# M3351 register map
File version: 1.0
Registers are 32-bit, read-write, reset 0x0 unless marked. A register's access mark holds for its fields unless they carry their own. Offsets are from the block's base; [hi:lo] are bit positions; 'fields as' and 'values as' point back to an identical list.

## TMR01 — TIMER Register Map
Base 0x40050000
Same registers: TMR01_NS 0x50050000
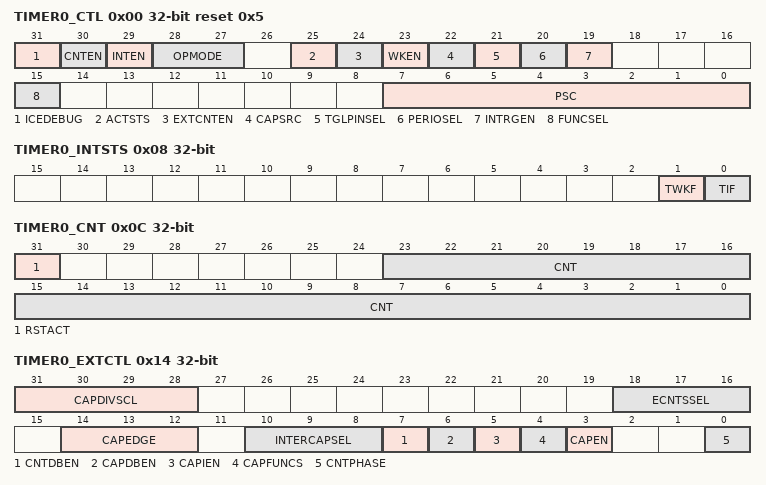
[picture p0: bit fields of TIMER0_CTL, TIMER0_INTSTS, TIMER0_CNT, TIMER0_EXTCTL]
0x00 TIMER0_CTL reset 0x5 — Timer0 Control Register
  [31] ICEDEBUG — ICE Debug Mode Acknowledge Disable Bit (Write Protect). TIMER counter will keep going no matter CPU is held by ICE or not. Note: This bit is write protected. Refer to the SYS_REGLCTL register.
    0=ICE debug mode acknowledgement effects TIMER counting; 1=ICE debug mode acknowledgement Disabled
  [30] CNTEN — Timer Counting Enable Bit. Note 3: Set enable/disable this bit needs 2 * TMR_CLK period to become active, user can read ACTSTS (TIMERx_CTL[25]) to check enable/disable command is completed or not.
    0=Stops/Suspends counting; 1=Starts counting
  [29] INTEN — Timer Interrupt Enable Bit. Note: If this bit is enabled, when the timer time-out interrupt flag TIF is set to 1, the timer interrupt signal is generated and inform to CPU.
    0=Timer time-out interrupt Disabled; 1=Timer time-out interrupt Enabled
  [28:27] OPMODE — Timer Counting Mode Select
    0=The timer controller is operated in One-shot mode; 1=The timer controller is operated in Periodic mode; 2=The timer controller is operated in Toggle-output mode; 3=The timer controller is operated in Continuous Counting mode
  [25] ACTSTS — Timer Active Status Bit (Read Only). This bit indicates the 24-bit up counter status. Note: This bit may active when CNT 0 transition to CNT 1.
    0=24-bit up counter is not active; 1=24-bit up counter is active
  [24] EXTCNTEN — Event Counter Mode Enable Bit. This bit is for external counting pin function enabled. Note: When timer is used as an event counter, this bit should be set to 1.
    0=Event counter mode Disabled; 1=Event counter mode Enabled
  [23] WKEN — Wake-up Function Enable Bit. If this bit is set to 1, while timer interrupt flag TIF (TIMERx_INTSTS[0]) is 1 and INTEN (TIMERx_CTL[29]) is enabled, the timer interrupt signal will generate a wake-up trigger event to CPU.
    0=Wake-up function Disabled if timer interrupt signal generated; 1=Wake-up function Enabled if timer interrupt signal generated
  [22] CAPSRC — Capture Pin Source Selection
    0=Capture Function source is from TMx_EXT (x= 0~3) pin; 1=Capture Function source is from internal ACMP output signal, internal clock (LIRC, HIRC), or external clock (HXT, LXT)
  [21] TGLPINSEL — Toggle-output Pin Select
    0=Toggle mode output to TMx (Timer Event Counter Pin); 1=Toggle mode output to TMx_EXT (Timer External Capture Pin)
  [20] PERIOSEL — Periodic Mode Behavior Selection Enable Bit. If updated CMPDAT value CNT, CNT will be reset to default value.
    0=The behavior selection in periodic mode is Disabled; 1=The behavior selection in periodic mode is Enabled
  [19] INTRGEN — Inter-timer Trigger Mode Enable Bit. Setting this bit will enable the inter-timer trigger capture function. The Timer0/2 will be in event counter mode and counting with external clock source or event.Also, Timer1/3 will be in trigger-counting mode of capture function. Note: For Timer1/3, this bit is ineffective and the read back value is always 0.
    0=Inter-Timer Trigger Capture mode Disabled; 1=Inter-Timer Trigger Capture mode Enabled
  [15] FUNCSEL — Function Selection
    0=Timer controller is used as timer function; 1=Timer controller is used as PWM function
  [7:0] PSC — Prescale Counter. Note: Updating the prescale counter value will reset internal 8-bit prescale counter and 24-bit up counter value.
0x04 TIMER0_CMP — Timer0 Comparator Register
  [23:0] CMPDAT — Timer Comparator Value. CMPDAT is a 24-bit compared value register. When the internal 24-bit up counter value is equal to CMPDAT value, the TIF (TIMERx_INTSTS[0] Timer Interrupt Flag) will be set to 1. Note 1: Never write 0x0 or 0x1 in CMPDAT field, or the core will run into unknown state. Note 2: When timer is operating at continuous counting mode, the 24-bit up counter will keep counting continuously even if user writes a new value into CMPDAT field. But if timer is operating at other modes, the 24-bit up counter will restart counting from 0 and using newest CMPDAT value to be the timer compared value while user writes a new value into CMPDAT field.
0x08 TIMER0_INTSTS — Timer0 Interrupt Status Register
  [1] TWKF — Timer Wake-up Flag. This bit indicates the interrupt wake-up flag status of timer. Note: This bit is cleared by writing 1 to it.
    0=Timer does not cause CPU wake-up; 1=CPU wake-up from Idle or Power-down mode if timer time-out interrupt signal generated
  [0] TIF — Timer Interrupt Flag. This bit indicates the interrupt flag status of Timer while 24-bit timer up counter CNT (TIMERx_CNT[23:0]) value reaches CMPDAT (TIMERx_CMP[23:0]) value. Note: This bit is cleared by writing 1 to it.
    0=No effect; 1=CNT value matches the CMPDAT value
0x0C TIMER0_CNT — Timer0 Data Register
  [31] RSTACT — Timer Data Register Reset Active (Read Only). This bit indicates if the counter reset operation active. When user writes this CNT register, timer starts to reset its internal 24-bit timer up-counter to 0 and reload 8-bit pre-scale counter. At the same time, timer set this flag to 1 to indicate the counter reset operation is in progress. Once the counter reset operation done, timer clear this bit to 0 automatically.
    0=Reset operation is done; 1=Reset operation triggered by writing TIMERx_CNT is in progress
  [23:0] CNT — Timer Data Register. Read operation: Read this register to get CNT value. For example: If EXTCNTEN (TIMERx_CTL[24]) is 0, user can read CNT value for getting current 24-bit counter value. If EXTCNTEN (TIMERx_CTL[24]) is 1, user can read CNT value for getting current 24-bit event input counter value. Write operation: Writing any value to this register will reset current CNT value to 0 and reload internal 8-bit prescale counter.
0x10 TIMER0_CAP ro — Timer0 Capture Data Register
  [23:0] CAPDAT — Timer Capture Data Register. When CAPEN (TIMERx_EXTCTL[3]) bit is set, CAPFUNCS (TIMERx_EXTCTL[4]) bit is 0, and a transition on TMx_EXT pin matched the CAPEDGE (TIMERx_EXTCTL[14:12]) setting, CAPIF (TIMERx_EINTSTS[0]) will be set to 1 and the current timer counter value CNT (TIMERx_CNT[23:0]) will be auto-loaded into this CAPDAT field.
0x14 TIMER0_EXTCTL — Timer0 External Control Register
  [31:28] CAPDIVSCL — Timer Capture Source Divider Scale. This bits indicate the divide scale for capture source divider. Note: Set INTERCAPSEL (TIMERx_EXTCTL[10:8]) and CAPSRC (TIMERx_CTL[22]) to select capture source.
    0=Capture source/1; 1=Capture source/2; 2=Capture source/4; 3=Capture source/8; 4=Capture source/16; 5=Capture source/32; 6=Capture source/64; 7=Capture source/128; 8=Capture source/256
  [18:16] ECNTSSEL — Event Counter Source Selection to Trigger Event Counter Function
    0=Event Counter input source is from external TMx (x= 0~3) pin; 1=Event Counter input source is from internal USB internal SOF output signal; 2=Event Counter input source is from internal ACMP0 output signal; 3=Event Counter input source is from internal ACMP1 output signal
  [14:12] CAPEDGE — Timer External Capture Pin Edge Detect. When first capture event is generated, the CNT (TIMERx_CNT[23:0]) will be reset to 0 and first CAPDAT (TIMERx_CAP[23:0]) should be to 0. Note: Set CAPSRC (TIMERx_CTL[22]) and INTERCAPSEL (TIMERx_EXTCTL[10:8]) to select capture source.
    0=Capture event occurred when detect falling edge transfer on TMx_EXT (x= 0~3) pin; 1=Capture event occurred when detect rising edge transfer on TMx_EXT (x= 0~3) pin; 2=Capture event occurred when detect both falling and rising edge transfer on TMx_EXT (x= 0~3) pin, and first capture event occurred at falling edge transfer; 3=Capture event occurred when detect both rising and falling edge transfer on TMx_EXT (x= 0~3) pin, and first capture event occurred at rising edge transfer; 6=First capture event occurred at falling edge, follows capture events are at rising edge transfer on TMx_EXT (x= 0~3) pin; 7=First capture event occurred at rising edge, follows capture events are at falling edge transfer on TMx_EXT (x= 0~3) pin
  [10:8] INTERCAPSEL — Internal Capture Source Select. Note: These bits only available when CAPSRC (TIMERx_CTL[22]) is 1.
    0=Capture Function source is from internal ACMP0 output signal; 1=Capture Function source is from internal ACMP1 output signal; 2=Capture Function source is from HXT; 3=Capture Function source is from LXT; 4=Capture Function source is from HIRC; 5=Capture Function source is from LIRC
  [7] CNTDBEN — Timer Counter Pin De-bounce Enable Bit. Note: If this bit is enabled, the edge detection of TMx pin is detected with de-bounce circuit.
    0=TMx (x= 0~3) pin de-bounce Disabled; 1=TMx (x= 0~3) pin de-bounce Enabled
  [6] CAPDBEN — Timer External Capture Pin De-bounce Enable Bit. Note: If this bit is enabled, the edge detection of TMx_EXT pin or ACMP output is detected with de-bounce circuit.
    0=TMx_EXT (x= 0~3) pin de-bounce or ACMP output de-bounce Disabled; 1=TMx_EXT (x= 0~3) pin de-bounce or ACMP output de-bounce Enabled
  [5] CAPIEN — Timer External Capture Interrupt Enable Bit
    0=TMx_EXT (x= 0~3) pin, ACMP, internal clock, or external clock detection Interrupt Disabled; 1=TMx_EXT (x= 0~3) pin, ACMP, internal clock, or external clock detection Interrupt Enabled
  [4] CAPFUNCS — Capture Function Selection
    0=External Capture Mode Enabled; 1=External Reset Mode Enabled
  [3] CAPEN — Timer Capture Enable Bit. This bit enables the capture input function. Note: When CAPEN is 1, user can set INTERCAPSEL (TIMERx_EXTCTL [10:8]) to select capture source.
    0=Capture source Disabled; 1=Capture source Enabled
  [0] CNTPHASE — Timer External Count Phase
    0=A falling edge of external counting pin will be counted; 1=A rising edge of external counting pin will be counted
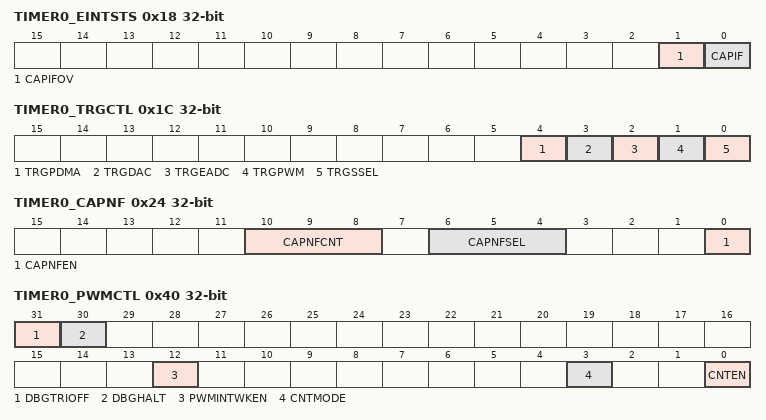
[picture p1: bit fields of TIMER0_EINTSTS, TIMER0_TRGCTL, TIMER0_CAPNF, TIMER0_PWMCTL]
0x18 TIMER0_EINTSTS — Timer0 External Interrupt Status Register
  [1] CAPIFOV — Capture Latch Interrupt Flag Overrun Status (Read Only). Note: This bit will be cleared automatically when user clears corresponding CAPIF.
    0=Capture latch happened when the corresponding CAPIF is 0; 1=Capture latch happened when the corresponding CAPIF is 1
  [0] CAPIF — Timer External Capture Interrupt Flag. This bit indicates the timer external capture interrupt flag status. Note 3: There is a new incoming capture event detected before CPU clearing the CAPIF status. If the above condition occurred, the Timer will keep register TIMERx_CAP unchanged and drop the new capture value.
    0=TMx_EXT (x= 0~3) pin, ACMP, internal clock, or external clock interrupt did not occur; 1=TMx_EXT (x= 0~3) pin, ACMP, internal clock, or external clock interrupt occurred
0x1C TIMER0_TRGCTL — Timer0 Trigger Control Register
  [4] TRGPDMA — Trigger PDMA Enable Bit. If this bit is set to 1, each timer time-out event or capture event can be triggered PDMA transfer.
    0=Timer interrupt trigger PDMA Disabled; 1=Timer interrupt trigger PDMA Enabled
  [3] TRGDAC — Trigger DAC Enable Bit. If this bit is set to 1, timer time-out interrupt or capture interrupt can be triggered DAC.
    0=Timer interrupt trigger DAC Disabled; 1=Timer interrupt trigger DAC Enabled
  [2] TRGEADC — Trigger EADC Enable Bit. If this bit is set to 1, each timer time-out event or capture event can be triggered EADC conversion.
    0=Timer interrupt trigger EADC Disabled; 1=Timer interrupt trigger EADC Enabled
  [1] TRGPWM — Trigger PWM/BPWM Enable Bit. If this bit is set to 1, each timer time-out event or capture event can be as PWM/BPWM counter clock source.
    0=Timer interrupt trigger PWM/BPWM Disabled; 1=Timer interrupt trigger PWM/BPWM Enabled
  [0] TRGSSEL — Trigger Source Select Bit. This bit is used to select internal trigger source is form timer time-out interrupt signal or capture interrupt signal.
    0=Time-out interrupt signal is used to internal trigger PWM, BPWM, PDMA, DAC and EADC; 1=Capture interrupt signal is used to internal trigger PWM, BPWM, PDMA, DAC and EADC
0x24 TIMER0_CAPNF — Timer0 Capture Input Noise Filter Register
  [10:8] CAPNFCNT — Capture Edge Detector Noise Filter Count. These bits control the capture filter counter to count from 0 to CAPNFCNT.
  [6:4] CAPNFSEL — Capture Edge Detector Noise Filter Clock Selection
    0=Noise filter clock is ECLKx; 1=Noise filter clock is ECLKx/2; 2=Noise filter clock is ECLKx/4; 3=Noise filter clock is ECLKx/8; 4=Noise filter clock is ECLKx/16; 5=Noise filter clock is ECLKx/32; 6=Noise filter clock is ECLKx/64; 7=Noise filter clock is ECLKx/128
  [0] CAPNFEN — Capture Noise Filter Enable Control
    0=Capture Noise Filter function Disabled; 1=Capture Noise Filter function Enabled
0x40 TIMER0_PWMCTL — Timer0 PWM Control Register
  [31] DBGTRIOFF — ICE Debug Mode Acknowledge Disable Bit (Write Protect). PWM output pin will keep output no matter ICE debug mode acknowledged or not. Note: This bit is write protected. Refer to SYS_REGLCTL control register.
    0=ICE debug mode acknowledgement effects PWM output; 1=ICE debug mode acknowledgement disabled
  [30] DBGHALT — ICE Debug Mode Counter Halt (Write Protect). If debug mode counter halt is enabled, PWM counter will keep current value until exit ICE debug mode. Note: This bit is write protected. Refer to SYS_REGLCTL control register.
    0=ICE debug mode counter halt Disabled; 1=ICE debug mode counter halt Enabled
  [12] PWMINTWKEN — PWM Interrupt Wake-up Enable Bit. If PWM interrupt occurs when chip is in Power-down mode, PWMINTWKEN can determine whether chip wake-up occurs or not.
    0=PWM interrupt wake-up Disabled; 1=PWM interrupt wake-up Enabled
  [3] CNTMODE — PWM Counter Mode
    0=Auto-reload mode; 1=One-shot mode
  [0] CNTEN — PWM Counter Enable Bit
    0=PWM counter and clock prescale Stop Running; 1=PWM counter and clock prescale Start Running
0x44 TIMER0_PWMCLKPSC — Timer0 PWM Counter Clock Pre-scale Register
  [7:0] CLKPSC — PWM Counter Clock Pre-scale. The active clock of PWM counter is decided by counter clock prescale and divided by (CLKPSC + 1). If CLKPSC is 0, then there is no scaling in PWM counter clock source.
0x48 TIMER0_PWMCNTCLR — Timer0 PWM Clear Counter Register
  [0] CNTCLR — Clear PWM Counter Control Bit. Note: When user writes this bit to 1, PWM counter will be cleared after (CLKPSC+16) TMRx_CLK cycles.
    0=No effect; 1=Write 1 to clear 16-bit PWM counter to 0x0000 in up count type
0x4C TIMER0_PWMPERIOD
  [15:0] PERIOD — PWM Period Register. In up count type: PWM counter counts from 0 to PERIOD, and restarts from 0. In up count type:
0x50 TIMER0_PWMCMPDAT — Timer0 PWM Comparator Register
  [15:0] CMP — PWM Comparator Register. PWM CMP is used to compare with PWM CNT to generate PWM output waveform, interrupt events and trigger EADC , PDMA, and DAC start conversion.
0x54 TIMER0_PWMCNT ro — Timer0 PWM Counter Register
  [15:0] CNT — PWM Counter Value Register (Read Only). User can monitor CNT to know the current counter value in 16-bit period counter.
0x58 TIMER0_PWMPOLCTL — Timer0 PWM Pin Output Polar Control Register
  [0] PINV — PWMx Output Pin Polar Control Bit. The bit is used to control polarity state of PWMx_OUT pin. Note: Set POSEL (TIMERx_PWMPOCTL[8]) to select TMx or TMx_EXT as PWMx output pin.
    0=PWMx_OUT pin polar inverse Disabled; 1=PWMx_OUT polar inverse Enabled
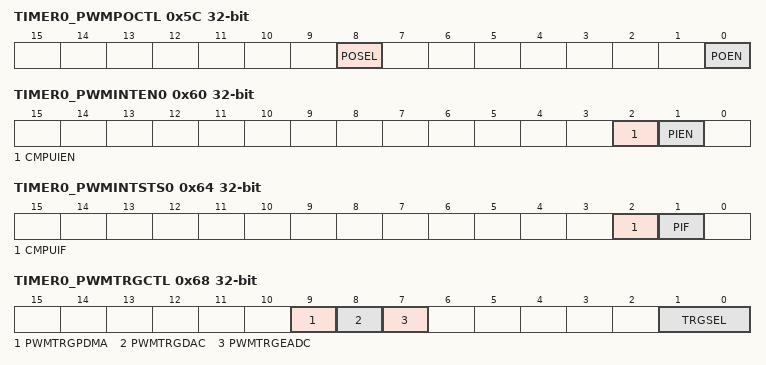
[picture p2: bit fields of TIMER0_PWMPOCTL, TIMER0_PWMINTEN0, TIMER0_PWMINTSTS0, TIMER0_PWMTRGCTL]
0x5C TIMER0_PWMPOCTL — Timer0 PWM Pin Output Control Register
  [8] POSEL — PWM Output Pin Select
    0=PWMx_OUT pin is TMx; 1=PWMx_OUT pin is TMx_EXT
  [0] POEN — PWMx Output Pin Enable Bit. Note: Set POSEL (TIMERx_PWMPOCTL[8]) to select TMx or TMx_EXT as PWMx output pin.
    0=PWMx_OUT pin at tri-state mode; 1=PWMx_OUT pin in output mode
0x60 TIMER0_PWMINTEN0 — Timer0 PWM Interrupt Enable Register 0
  [2] CMPUIEN — PWM Compare Up Count Interrupt Enable Bit
    0=Compare up count interrupt Disabled; 1=Compare up count interrupt Enabled
  [1] PIEN — PWM Period Point Interrupt Enable Bit
    0=Period point interrupt Disabled; 1=Period point interrupt Enabled
0x64 TIMER0_PWMINTSTS0 — Timer0 PWM Interrupt Status Register 0
  [2] CMPUIF — PWM Compare Up Count Interrupt Flag. This bit is set by hardware when TIMERx_PWM counter in up count direction and reaches CMP. Note 1: If CMP is equal to PERIOD, there is no CMPUIF flag in up count type. Note 2: This bit is cleared by writing 1 to it.
  [1] PIF — PWM Period Point Interrupt Flag. This bit is set by hardware when TIMERx_PWM counter reaches PERIOD. Note: This bit is cleared by writing 1 to it.
0x68 TIMER0_PWMTRGCTL — Timer0 PWM Trigger Control Register
  [9] PWMTRGPDMA — PWM Counter Event Trigger PDMA Conversion Enable Bit. If this bit is set to 1, PWM can trigger PDMA conversion. Note: Set TRGSEL (TIMERx_PWMTRGCTL[1:0]) to select PWM trigger conversion source.
    0=PWM trigger PDMA Disabled; 1=PWM trigger PDMA Enabled
  [8] PWMTRGDAC — PWM Counter Event Trigger DAC Conversion Enable Bit. If this bit is set to 1, PWM can trigger DAC conversion. Note: Set TRGSEL (TIMERx_PWMTRGCTL[1:0]) to select PWM trigger conversion source.
    0=PWM trigger DAC Disabled; 1=PWM trigger DAC Enabled
  [7] PWMTRGEADC — PWM Counter Event Trigger EADC Conversion Enable Bit. Note: Set TRGSEL (TIMERx_PWMTRGCTL[1:0]) to select PWM trigger conversion source.
    0=PWM counter event trigger EADC conversion Disabled; 1=PWM counter event trigger EADC conversion Enabled
  [1:0] TRGSEL — PWM Counter Event Source Select to Trigger Conversion
    0=Trigger conversion at period point (PIF); 1=Trigger conversion at compare up count point (CMPUIF); 2=Trigger conversion at period or compare up count point (PIF or CMPUIF)
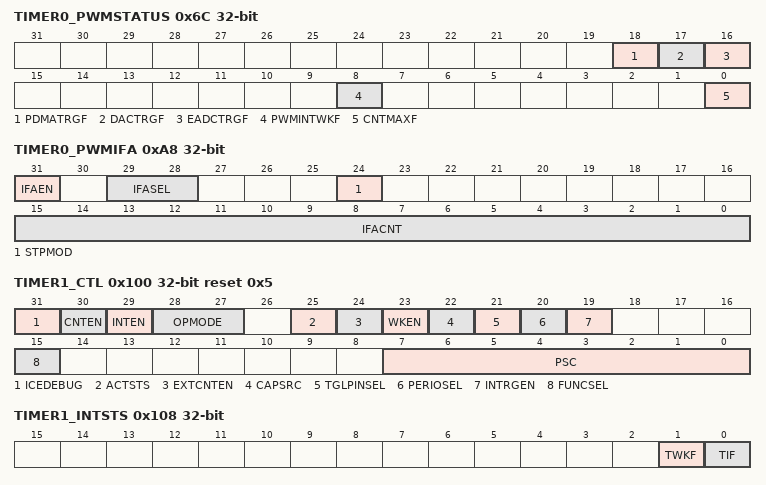
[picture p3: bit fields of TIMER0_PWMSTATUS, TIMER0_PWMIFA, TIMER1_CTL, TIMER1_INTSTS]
0x6C TIMER0_PWMSTATUS
  [18] PDMATRGF — Trigger PDMA Start Conversion Flag. Note: This bit is cleared by writing 1 to it.
    0=PWM counter event trigger PDMA start conversion has not occurred; 1=PWM counter event trigger PDMA start conversion has occurred
  [17] DACTRGF — Trigger DAC Start Conversion Flag. Note: This bit is cleared by writing 1 to it.
    0=PWM counter event trigger DAC start conversion has not occurred; 1=PWM counter event trigger DAC start conversion has occurred
  [16] EADCTRGF — Trigger EADC Start Conversion Flag. Note: This bit is cleared by writing 1 to it.
    0=PWM counter event trigger EADC start conversion is not occurred; 1=PWM counter event trigger EADC start conversion has occurred
  [8] PWMINTWKF — PWM Interrupt Wake-up Flag. Note: This bit is cleared by writing 1 to it.
    0=PWM interrupt wake-up has not occurred; 1=PWM interrupt wake-up has occurred
  [0] CNTMAXF — PWM Counter Equal to 0xFFFF Flag. Note: This bit is cleared by writing 1 to it.
    0=The PWM counter value never reached its maximum value 0xFFFF; 1=The PWM counter value has reached its maximum value
0x70 TIMER0_PWMPBUF ro — Timer0 PWM Period Buffer Register
  [15:0] PBUF — PWM Period Buffer Register (Read Only). Used as PERIOD active register.
0x74 TIMER0_PWMCMPBUF ro — Timer0 PWM Comparator Buffer Register
  [15:0] CMPBUF — PWM Comparator Buffer Register (Read Only). Used as CMP active register.
0xA8 TIMER0_PWMIFA — Timer0 PWM Interrupt Flag Accumulator Register
  [31] IFAEN — PWM Interrupt Flag Accumulator Enable Bit
    0=PWM interrupt flag accumulator function Disabled; 1=PWM interrupt flag accumulator function Enabled
  [29:28] IFASEL — PWM Interrupt Flag Accumulator Source Select
    1=Accumulate at each PWM period point; 2=Accumulate at each PWM up-count compared point
  [24] STPMOD — PWM Accumulator Stop Mode Enable Bit
    0=PWM interrupt accumulator event to stop counting Disabled; 1=PWM interrupt accumulator event to stop counting Enabled
  [15:0] IFACNT — PWM Interrupt Flag Accumulator Counter. This field sets the count number which defines (IFACNT+1) times of specify PWM interrupt occurs to set IFAIF bit to request the PWM accumulator interrupt. PWM accumulator flag (IFAIF) will be set in every (IFACNT+1) times during the PWM counter operation.
0xAC TIMER0_PWMAINTSTS — Timer0 PWM Accumulator Interrupt Flag Register
  [0] IFAIF — PWM Interrupt Flag Accumulator Interrupt Flag. This bit is set by hardware when the accumulator value reaches (IFACNT+1). Note 1: This bit is cleared by writing 1 to it. Note 2: If APDMAEN (TIMERx_PWMAPDMACTL[0]) is set, this bit will be auto clear after PDMA transfer done.
0xB0 TIMER0_PWMAINTEN — Timer0 PWM Accumulator Interrupt Enable Register
  [0] IFAIEN — PWM Interrupt Flag Accumulator Interrupt Enable Bit
    0=Interrupt Flag Accumulator interrupt Disabled; 1=Interrupt Flag Accumulator interrupt Enabled
0xB4 TIMER0_PWMAPDMACTL — Timer0 PWM Accumulator PDMA Control Register
  [0] APDMAEN — PWM Accumulator PDMA Enable Bit
    0=PWM interrupt accumulator event to trigger PDMA transfer Disabled; 1=PWM interrupt accumulator event to trigger PDMA transfer Enabled
0x100 TIMER1_CTL reset 0x5 — Timer1 Control Register
  fields as TIMER0_CTL
0x104 TIMER1_CMP — Timer1 Comparator Register
  fields as TIMER0_CMP
0x108 TIMER1_INTSTS — Timer1 Interrupt Status Register
  fields as TIMER0_INTSTS
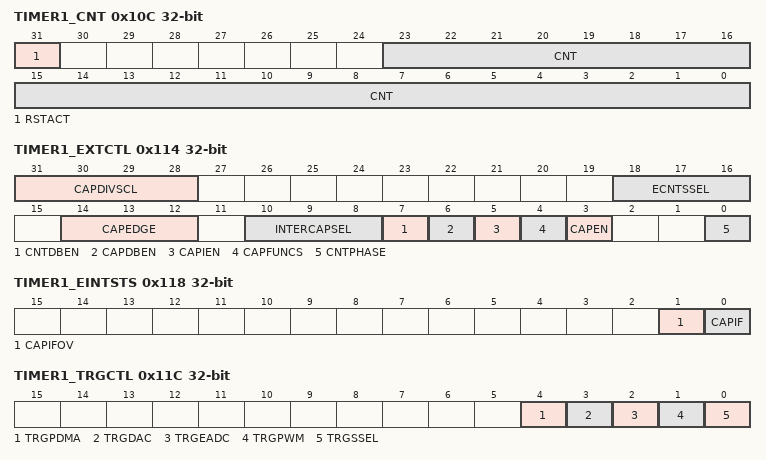
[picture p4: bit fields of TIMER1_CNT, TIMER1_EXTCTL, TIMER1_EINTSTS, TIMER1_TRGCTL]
0x10C TIMER1_CNT — Timer1 Data Register
  fields as TIMER0_CNT
0x110 TIMER1_CAP ro — Timer1 Capture Data Register
  fields as TIMER0_CAP
0x114 TIMER1_EXTCTL — Timer1 External Control Register
  fields as TIMER0_EXTCTL
0x118 TIMER1_EINTSTS — Timer1 External Interrupt Status Register
  fields as TIMER0_EINTSTS
0x11C TIMER1_TRGCTL — Timer1 Trigger Control Register
  fields as TIMER0_TRGCTL
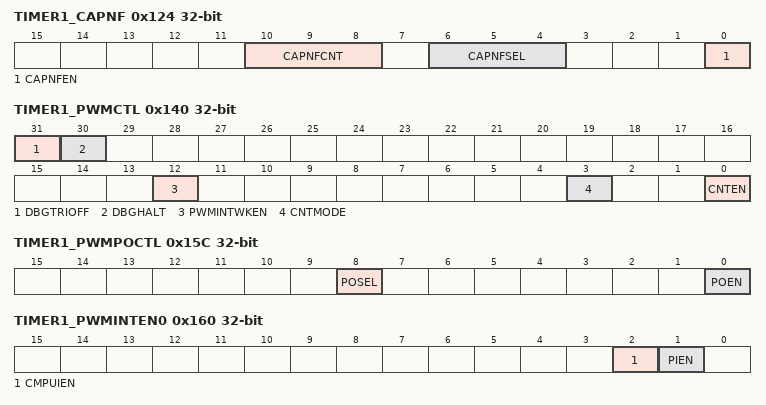
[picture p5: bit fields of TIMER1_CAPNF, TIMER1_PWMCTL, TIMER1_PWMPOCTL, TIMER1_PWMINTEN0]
0x124 TIMER1_CAPNF — Timer1 Capture Input Noise Filter Register
  fields as TIMER0_CAPNF
0x140 TIMER1_PWMCTL — Timer1 PWM Control Register
  fields as TIMER0_PWMCTL
0x144 TIMER1_PWMCLKPSC — Timer1 PWM Counter Clock Pre-scale Register
  fields as TIMER0_PWMCLKPSC
0x148 TIMER1_PWMCNTCLR — Timer1 PWM Clear Counter Register
  fields as TIMER0_PWMCNTCLR
0x14C TIMER1_PWMPERIOD
  fields as TIMER0_PWMPERIOD
0x150 TIMER1_PWMCMPDAT — Timer1 PWM Comparator Register
  fields as TIMER0_PWMCMPDAT
0x154 TIMER1_PWMCNT ro — Timer1 PWM Counter Register
  fields as TIMER0_PWMCNT
0x158 TIMER1_PWMPOLCTL — Timer1 PWM Pin Output Polar Control Register
  fields as TIMER0_PWMPOLCTL
0x15C TIMER1_PWMPOCTL — Timer1 PWM Pin Output Control Register
  fields as TIMER0_PWMPOCTL
0x160 TIMER1_PWMINTEN0 — Timer1 PWM Interrupt Enable Register 0
  fields as TIMER0_PWMINTEN0
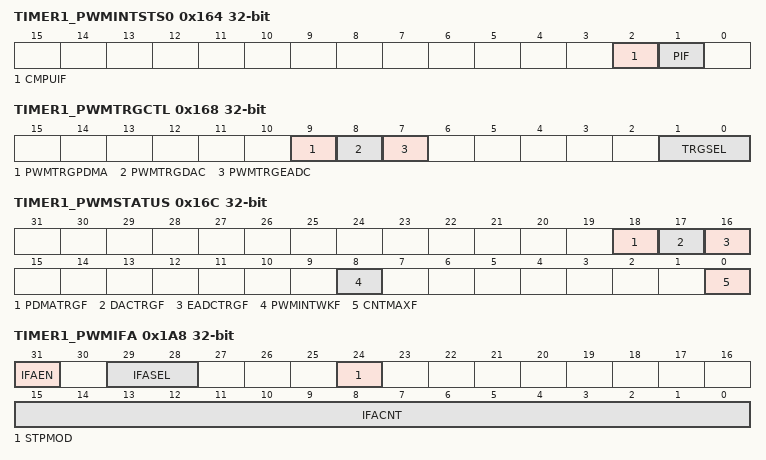
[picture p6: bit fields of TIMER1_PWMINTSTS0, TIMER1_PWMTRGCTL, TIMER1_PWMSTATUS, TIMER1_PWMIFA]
0x164 TIMER1_PWMINTSTS0 — Timer1 PWM Interrupt Status Register 0
  fields as TIMER0_PWMINTSTS0
0x168 TIMER1_PWMTRGCTL — Timer1 PWM Trigger Control Register
  fields as TIMER0_PWMTRGCTL
0x16C TIMER1_PWMSTATUS
  fields as TIMER0_PWMSTATUS
0x170 TIMER1_PWMPBUF ro — Timer1 PWM Period Buffer Register
  fields as TIMER0_PWMPBUF
0x174 TIMER1_PWMCMPBUF ro — Timer1 PWM Comparator Buffer Register
  fields as TIMER0_PWMCMPBUF
0x1A8 TIMER1_PWMIFA — Timer1 PWM Interrupt Flag Accumulator Register
  fields as TIMER0_PWMIFA
0x1AC TIMER1_PWMAINTSTS — Timer1 PWM Accumulator Interrupt Flag Register
  fields as TIMER0_PWMAINTSTS
0x1B0 TIMER1_PWMAINTEN — Timer1 PWM Accumulator Interrupt Enable Register
  fields as TIMER0_PWMAINTEN
0x1B4 TIMER1_PWMAPDMACTL — Timer1 PWM Accumulator PDMA Control Register
  fields as TIMER0_PWMAPDMACTL
